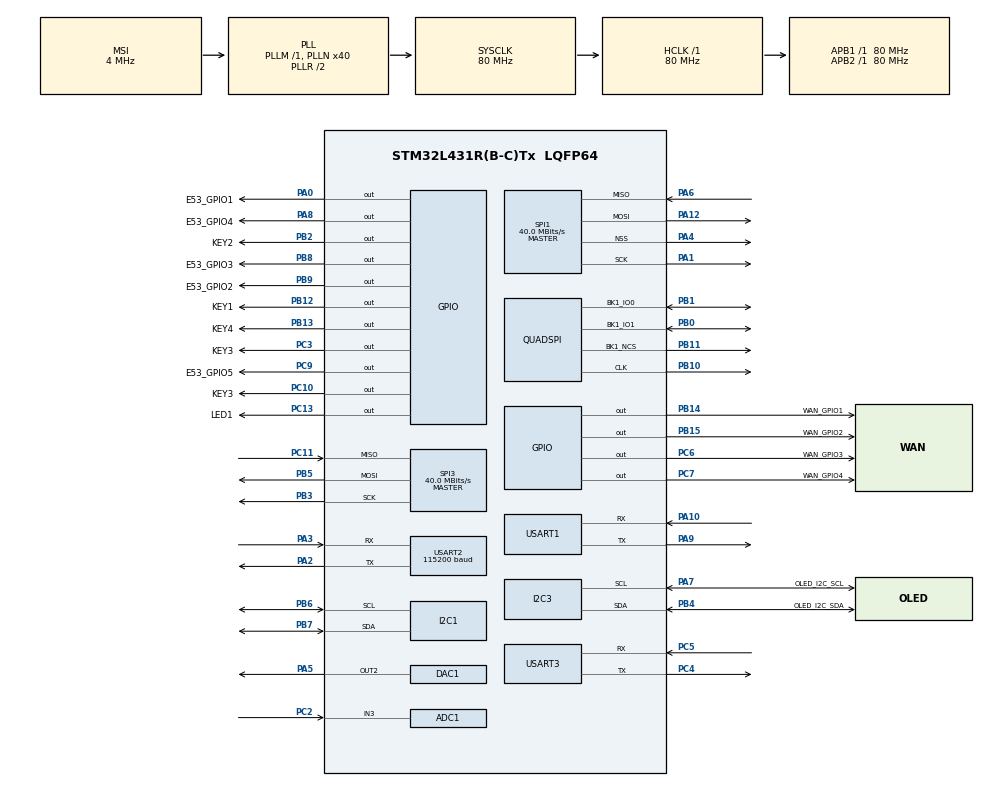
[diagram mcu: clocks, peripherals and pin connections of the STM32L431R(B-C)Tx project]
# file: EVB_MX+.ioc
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ADC1.Channel-0\#ChannelRegularConversion=ADC_CHANNEL_3
ADC1.ContinuousConvMode=ENABLE
ADC1.NbrOfConversion=1
ADC1.NbrOfConversionFlag=1
ADC1.OffsetNumber-0\#ChannelRegularConversion=ADC_OFFSET_NONE
ADC1.Rank-0\#ChannelRegularConversion=1
ADC1.SamplingTime-0\#ChannelRegularConversion=ADC_SAMPLETIME_247CYCLES_5
ADC1.master=1
DAC1.DAC_Channel-DAC_OUT2=DAC_CHANNEL_2
Dma.ADC1.0.Direction=DMA_PERIPH_TO_MEMORY
Dma.ADC1.0.Instance=DMA1_Channel1
Dma.ADC1.0.MemDataAlignment=DMA_MDATAALIGN_HALFWORD
Dma.ADC1.0.MemInc=DMA_MINC_ENABLE
Dma.ADC1.0.Mode=DMA_CIRCULAR
Dma.ADC1.0.PeriphDataAlignment=DMA_PDATAALIGN_HALFWORD
Dma.ADC1.0.PeriphInc=DMA_PINC_DISABLE
Dma.ADC1.0.Priority=DMA_PRIORITY_MEDIUM
Dma.Request0=ADC1
I2C1.Timing=0x10909CEC
I2C3.Timing=0x10909CEC
Mcu.Family=STM32L4
Mcu.Name=STM32L431R(B-C)Tx
Mcu.Package=LQFP64
NVIC.ADC1_IRQn=true\:3\:1\:true\:false\:true\:true\:true\:true
NVIC.DMA1_Channel1_IRQn=true\:3\:0\:true\:false\:true\:false\:true\:true
NVIC.PriorityGroup=NVIC_PRIORITYGROUP_2
NVIC.USART2_IRQn=true\:3\:2\:true\:false\:true\:true\:true\:true
PA0.GPIO_Label=E53_GPIO1
PA0.Signal=GPIO_Output
PA1.Mode=Full_Duplex_Master
PA1.Signal=SPI1_SCK
PA10.Mode=Asynchronous
PA10.Signal=USART1_RX
PA12.Mode=Full_Duplex_Master
PA12.Signal=SPI1_MOSI
PA13\ (JTMS-SWDIO).Mode=Serial_Wire
PA13\ (JTMS-SWDIO).Signal=SYS_JTMS-SWDIO
PA14\ (JTCK-SWCLK).Mode=Serial_Wire
PA14\ (JTCK-SWCLK).Signal=SYS_JTCK-SWCLK
PA15\ (JTDI).Signal=SPI3_NSS
PA2.Mode=Asynchronous
PA2.Signal=USART2_TX
PA3.Mode=Asynchronous
PA3.Signal=USART2_RX
PA4.Mode=NSS_Signal_Hard_Output
PA4.Signal=SPI1_NSS
PA5.Signal=COMP_DAC12_group
PA6.Mode=Full_Duplex_Master
PA6.Signal=SPI1_MISO
PA7.GPIO_Label=OLED_I2C_SCL
PA7.Mode=I2C
PA7.Signal=I2C3_SCL
PA8.GPIO_Label=E53_GPIO4
PA8.Signal=GPIO_Output
PA9.Mode=Asynchronous
PA9.Signal=USART1_TX
PB0.Mode=Single Bank 1 2IOs
PB0.Signal=QUADSPI_BK1_IO1
PB1.Mode=Single Bank 1 2IOs
PB1.Signal=QUADSPI_BK1_IO0
PB10.Mode=Single Bank 1 2IOs
PB10.Signal=QUADSPI_CLK
PB11.Mode=Single Bank 1 2IOs
PB11.Signal=QUADSPI_BK1_NCS
PB12.GPIO_Label=KEY1
PB12.Signal=GPIO_Output
PB13.GPIO_Label=KEY4
PB13.Signal=GPIO_Output
PB14.GPIO_Label=WAN_GPIO1
PB14.Signal=GPIO_Output
PB15.GPIO_Label=WAN_GPIO2
PB15.Signal=GPIO_Output
PB2.GPIO_Label=KEY2
PB2.GPIO_ModeDefaultOutputPP=GPIO_MODE_OUTPUT_PP
PB2.GPIO_PuPd=GPIO_PULLUP
PB2.GPIO_Speed=GPIO_SPEED_FREQ_MEDIUM
PB2.PinState=GPIO_PIN_SET
PB2.Signal=GPIO_Output
PB3\ (JTDO-TRACESWO).Mode=Full_Duplex_Master
PB3\ (JTDO-TRACESWO).Signal=SPI3_SCK
PB4\ (NJTRST).GPIO_Label=OLED_I2C_SDA
PB4\ (NJTRST).Mode=I2C
PB4\ (NJTRST).Signal=I2C3_SDA
PB5.Mode=Full_Duplex_Master
PB5.Signal=SPI3_MOSI
PB6.Mode=I2C
PB6.Signal=I2C1_SCL
PB7.Mode=I2C
PB7.Signal=I2C1_SDA
PB8.GPIO_Label=E53_GPIO3
PB8.Signal=GPIO_Output
PB9.GPIO_Label=E53_GPIO2
PB9.Signal=GPIO_Output
PC0.Signal=LPTIM1_IN1
PC1.Signal=LPUART1_TX
PC10.GPIO_Label=KEY3
PC10.Signal=GPIO_Output
PC11.Mode=Full_Duplex_Master
PC11.Signal=SPI3_MISO
PC12.Signal=SDMMC1_CK
PC13.GPIO_Label=LED1
PC13.Signal=GPIO_Output
PC14-OSC32_IN\ (PC14).Mode=LSE-External-Oscillator
PC14-OSC32_IN\ (PC14).Signal=RCC_OSC32_IN
PC15-OSC32_OUT\ (PC15).Mode=LSE-External-Oscillator
PC15-OSC32_OUT\ (PC15).Signal=RCC_OSC32_OUT
PC2.Signal=ADCx_IN3
PC3.GPIO_Label=KEY3
PC3.GPIO_ModeDefaultOutputPP=GPIO_MODE_OUTPUT_PP
PC3.GPIO_PuPd=GPIO_PULLUP
PC3.GPIO_Speed=GPIO_SPEED_FREQ_MEDIUM
PC3.PinState=GPIO_PIN_SET
PC3.Signal=GPIO_Output
PC4.Mode=Asynchronous
PC4.Signal=USART3_TX
PC5.Mode=Asynchronous
PC5.Signal=USART3_RX
PC6.GPIO_Label=WAN_GPIO3
PC6.Signal=GPIO_Output
PC7.GPIO_Label=WAN_GPIO4
PC7.Signal=GPIO_Output
PC8.Signal=SDMMC1_D0
PC9.GPIO_Label=E53_GPIO5
PC9.Signal=GPIO_Output
PD2.Signal=SDMMC1_CMD
PH0-OSC_IN\ (PH0).Mode=HSE-External-Oscillator
PH0-OSC_IN\ (PH0).Signal=RCC_OSC_IN
PH1-OSC_OUT\ (PH1).Mode=HSE-External-Oscillator
PH1-OSC_OUT\ (PH1).Signal=RCC_OSC_OUT
ProjectManager.HeapSize=0x200
ProjectManager.StackSize=0x400
ProjectManager.TargetToolchain=MDK-ARM V5.32
RCC.ADCFreq_Value=32000000
RCC.AHBFreq_Value=80000000
RCC.APB1Freq_Value=80000000
RCC.APB1TimFreq_Value=80000000
RCC.APB2Freq_Value=80000000
RCC.APB2TimFreq_Value=80000000
RCC.CortexFreq_Value=80000000
RCC.HCLKFreq_Value=80000000
RCC.HSE_VALUE=8000000
RCC.HSI48_VALUE=48000000
RCC.HSI_VALUE=16000000
RCC.LSE_Drive_CapabilityArg=+LSE_Drive_Capability
RCC.MSIAutoCalibration=DISABLED
RCC.MSI_VALUE=4000000
RCC.PLLN=40
RCC.PLLSAI1N=16
RCC.SYSCLKFreq_VALUE=80000000
RCC.SYSCLKSource=RCC_SYSCLKSOURCE_PLLCLK
RCC.VCOOutputFreq_Value=160000000
SH.ADCx_IN3.0=ADC1_IN3,IN3-Single-Ended
SH.COMP_DAC12_group.0=DAC1_OUT2,DAC_OUT2
SPI1.BaudRatePrescaler=SPI_BAUDRATEPRESCALER_2
SPI1.CalculateBaudRate=40.0 MBits/s
SPI1.Direction=SPI_DIRECTION_2LINES
SPI1.Mode=SPI_MODE_MASTER
SPI1.VirtualNSS=VM_NSSHARD
SPI1.VirtualType=VM_MASTER
SPI3.CalculateBaudRate=40.0 MBits/s
SPI3.Direction=SPI_DIRECTION_2LINES
SPI3.Mode=SPI_MODE_MASTER
SPI3.VirtualType=VM_MASTER
USART1.VirtualMode-Asynchronous=VM_ASYNC
USART2.BaudRate=115200
USART2.VirtualMode-Asynchronous=VM_ASYNC
USART3.VirtualMode-Asynchronous=VM_ASYNC
board=custom

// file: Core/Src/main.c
/* USER CODE BEGIN Header */
/**
  ******************************************************************************
  * @file           : main.c
  * @brief          : Main program body
  ******************************************************************************
  * @attention
  *
  * Copyright (c) 2024 STMicroelectronics.
  * All rights reserved.
  *
  * This software is licensed under terms that can be found in the LICENSE file
  * in the root directory of this software component.
  * If no LICENSE file comes with this software, it is provided AS-IS.
  *
  ******************************************************************************
  */
/* USER CODE END Header */
#include "main.h"
#include "adc.h"
#include "dac.h"
#include "dma.h"
#include "i2c.h"
#include "quadspi.h"
#include "spi.h"
#include "usart.h"
#include "gpio.h"

/* USER CODE BEGIN Includes */
#include "oled.h"
/* USER CODE END Includes */

void SystemClock_Config(void);

int main(void)
{
  /* USER CODE BEGIN 1 */
  char *str = "Hello Wrold";
  /* USER CODE END 1 */

  /* MCU Configuration--------------------------------------------------------*/

  /* Reset of all peripherals, Initializes the Flash interface and the Systick. */
  HAL_Init();

  /* Configure the system clock */
  SystemClock_Config();

  /* Initialize all configured peripherals */
  MX_GPIO_Init();
  MX_DMA_Init();
  MX_ADC1_Init();
  MX_USART2_UART_Init();
  MX_DAC1_Init();
  MX_I2C1_Init();
  MX_I2C3_Init();
  MX_QUADSPI_Init();
  MX_SPI1_Init();
  MX_SPI3_Init();
  MX_USART1_UART_Init();
  MX_USART3_UART_Init();
  /* USER CODE BEGIN 2 */
  OLED_Init();
  OLED_Clear();
	OLED_DrawLine(0,8,127,8);
	OLED_Refresh();
	OLED_ShowString(0,2,(uint8_t *)"Hello Wrold",16);
  /* USER CODE END 2 */
  /* Infinite loop */
  while (1)
  {
  }
}

void SystemClock_Config(void)
{
  RCC_OscInitTypeDef RCC_OscInitStruct = {0};
  RCC_ClkInitTypeDef RCC_ClkInitStruct = {0};

  /** Configure the main internal regulator output voltage
  */
  if (HAL_PWREx_ControlVoltageScaling(PWR_REGULATOR_VOLTAGE_SCALE1) != HAL_OK)
  {
    Error_Handler();
  }

  /** Initializes the RCC Oscillators according to the specified parameters
  * in the RCC_OscInitTypeDef structure.
  */
  RCC_OscInitStruct.OscillatorType = RCC_OSCILLATORTYPE_MSI;
  RCC_OscInitStruct.MSIState = RCC_MSI_ON;
  RCC_OscInitStruct.MSICalibrationValue = 0;
  RCC_OscInitStruct.MSIClockRange = RCC_MSIRANGE_6;
  RCC_OscInitStruct.PLL.PLLState = RCC_PLL_ON;
  RCC_OscInitStruct.PLL.PLLSource = RCC_PLLSOURCE_MSI;
  RCC_OscInitStruct.PLL.PLLM = 1;
  RCC_OscInitStruct.PLL.PLLN = 40;
  RCC_OscInitStruct.PLL.PLLP = RCC_PLLP_DIV7;
  RCC_OscInitStruct.PLL.PLLQ = RCC_PLLQ_DIV2;
  RCC_OscInitStruct.PLL.PLLR = RCC_PLLR_DIV2;
  if (HAL_RCC_OscConfig(&RCC_OscInitStruct) != HAL_OK)
  {
    Error_Handler();
  }

  /** Initializes the CPU, AHB and APB buses clocks
  */
  RCC_ClkInitStruct.ClockType = RCC_CLOCKTYPE_HCLK|RCC_CLOCKTYPE_SYSCLK
                              |RCC_CLOCKTYPE_PCLK1|RCC_CLOCKTYPE_PCLK2;
  RCC_ClkInitStruct.SYSCLKSource = RCC_SYSCLKSOURCE_PLLCLK;
  RCC_ClkInitStruct.AHBCLKDivider = RCC_SYSCLK_DIV1;
  RCC_ClkInitStruct.APB1CLKDivider = RCC_HCLK_DIV1;
  RCC_ClkInitStruct.APB2CLKDivider = RCC_HCLK_DIV1;

  if (HAL_RCC_ClockConfig(&RCC_ClkInitStruct, FLASH_LATENCY_4) != HAL_OK)
  {
    Error_Handler();
  }
}

void Error_Handler(void)
{
  __disable_irq();
  while (1)
  {
  }
}
